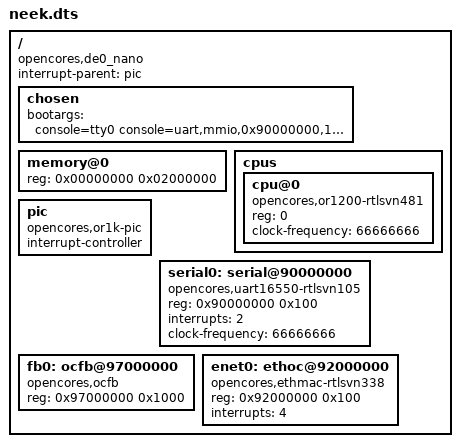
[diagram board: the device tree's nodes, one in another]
/dts-v1/;
/ {
	compatible = "opencores,de0_nano";
	#address-cells = <1>;
	#size-cells = <1>;
	interrupt-parent = <&pic>;

	chosen {
		bootargs = "console=tty0 console=uart,mmio,0x90000000,115200 video=ocfb:800x600-16@60";
	};

	memory@0 {
		device_type = "memory";
		reg = <0x00000000 0x02000000>;
	};

	cpus {
		#address-cells = <1>;
		#size-cells = <0>;
		cpu@0 {
			compatible = "opencores,or1200-rtlsvn481";
			reg = <0>;
			clock-frequency = <66666666>;
		};
	};

	/*
	 * OR1K PIC is built into CPU and accessed via special purpose
	 * registers.  It is not addressable and, hence, has no 'reg'
	 * property.
	 */
	pic: pic {
		compatible = "opencores,or1k-pic";
		#interrupt-cells = <1>;
		interrupt-controller;
	};

	serial0: serial@90000000 {
		compatible = "opencores,uart16550-rtlsvn105", "ns16550a";
		reg = <0x90000000 0x100>;
		interrupts = <2>;
		clock-frequency = <66666666>;
	};

	fb0: ocfb@97000000 {
		compatible = "opencores,ocfb";
		reg = <0x97000000 0x1000>;
	};

	enet0: ethoc@92000000 {
		compatible = "opencores,ethmac-rtlsvn338";
		reg = <0x92000000 0x100>;
		interrupts = <4>;
	};

};
